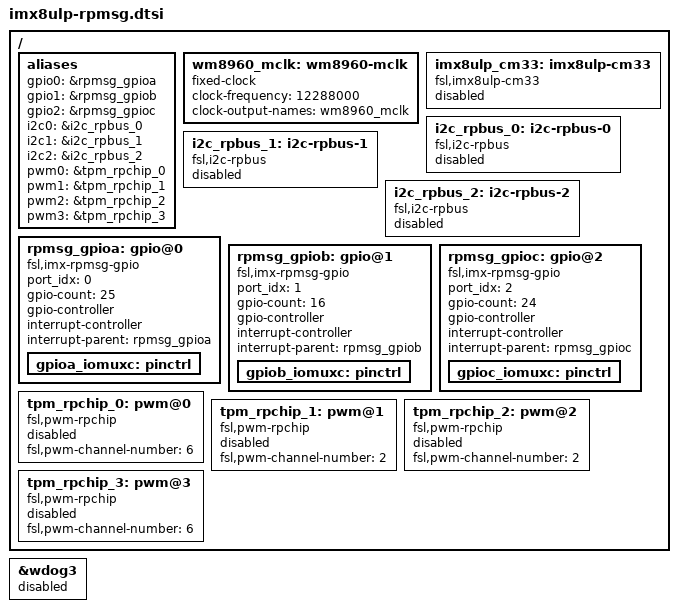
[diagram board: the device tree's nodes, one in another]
// SPDX-License-Identifier: (GPL-2.0+ OR MIT)
/*
 * Copyright 2021 NXP
 */

#include "imx8ulp-pinfunc-m33.h"

/ {
	aliases {
		gpio0 = &rpmsg_gpioa;
		gpio1 = &rpmsg_gpiob;
		gpio2 = &rpmsg_gpioc;
		i2c0 = &i2c_rpbus_0;
		i2c1 = &i2c_rpbus_1;
		i2c2 = &i2c_rpbus_2;
		pwm0 = &tpm_rpchip_0;
		pwm1 = &tpm_rpchip_1;
		pwm2 = &tpm_rpchip_2;
		pwm3 = &tpm_rpchip_3;
	};

	wm8960_mclk: wm8960-mclk {
		compatible = "fixed-clock";
		clock-frequency = <12288000>;
		clock-output-names = "wm8960_mclk";
		#clock-cells = <0>;
	};

	imx8ulp_cm33: imx8ulp-cm33 {
		compatible = "fsl,imx8ulp-cm33", "fsl,imx7ulp-cm4";
		status = "disabled";
	};

	i2c_rpbus_0: i2c-rpbus-0 {
		compatible = "fsl,i2c-rpbus";
		status = "disabled";
	};

	i2c_rpbus_1: i2c-rpbus-1 {
		compatible = "fsl,i2c-rpbus";
		status = "disabled";
	};

	i2c_rpbus_2: i2c-rpbus-2 {
		compatible = "fsl,i2c-rpbus";
		status = "disabled";
	};

	rpmsg_gpioa: gpio@0 {
		compatible = "fsl,imx-rpmsg-gpio";
		port_idx = <0>;
		gpio-count = <25>;
		gpio-controller;
		#gpio-cells = <2>;
		#interrupt-cells = <2>;
		interrupt-controller;
		interrupt-parent = <&rpmsg_gpioa>;
		status = "okay";
		gpioa_iomuxc: pinctrl {
		};
	};

	rpmsg_gpiob: gpio@1 {
		compatible = "fsl,imx-rpmsg-gpio";
		port_idx = <1>;
		gpio-count = <16>;
		gpio-controller;
		#gpio-cells = <2>;
		#interrupt-cells = <2>;
		interrupt-controller;
		interrupt-parent = <&rpmsg_gpiob>;
		status = "okay";
		gpiob_iomuxc: pinctrl {
		};
	};

	rpmsg_gpioc: gpio@2 {
		compatible = "fsl,imx-rpmsg-gpio";
		port_idx = <2>;
		gpio-count = <24>;
		gpio-controller;
		#gpio-cells = <2>;
		#interrupt-cells = <2>;
		interrupt-controller;
		interrupt-parent = <&rpmsg_gpioc>;
		status = "okay";
		gpioc_iomuxc: pinctrl {
		};
	};

	tpm_rpchip_0: pwm@0 {
		compatible = "fsl,pwm-rpchip";
		#pwm-cells = <3>;
		fsl,pwm-channel-number = <6>;
		status = "disabled";
	};

	tpm_rpchip_1: pwm@1 {
		compatible = "fsl,pwm-rpchip";
		#pwm-cells = <3>;
		fsl,pwm-channel-number = <2>;
		status = "disabled";
	};

	tpm_rpchip_2: pwm@2 {
		compatible = "fsl,pwm-rpchip";
		#pwm-cells = <3>;
		fsl,pwm-channel-number = <2>;
		status = "disabled";
	};

	tpm_rpchip_3: pwm@3 {
		compatible = "fsl,pwm-rpchip";
		#pwm-cells = <3>;
		fsl,pwm-channel-number = <6>;
		status = "disabled";
	};
};

&wdog3 {
	/* prefer wdog over rpmsg by default. This one does not
	 * allow restarting m33 core so is useless in practice. */
	status = "disabled";
};
